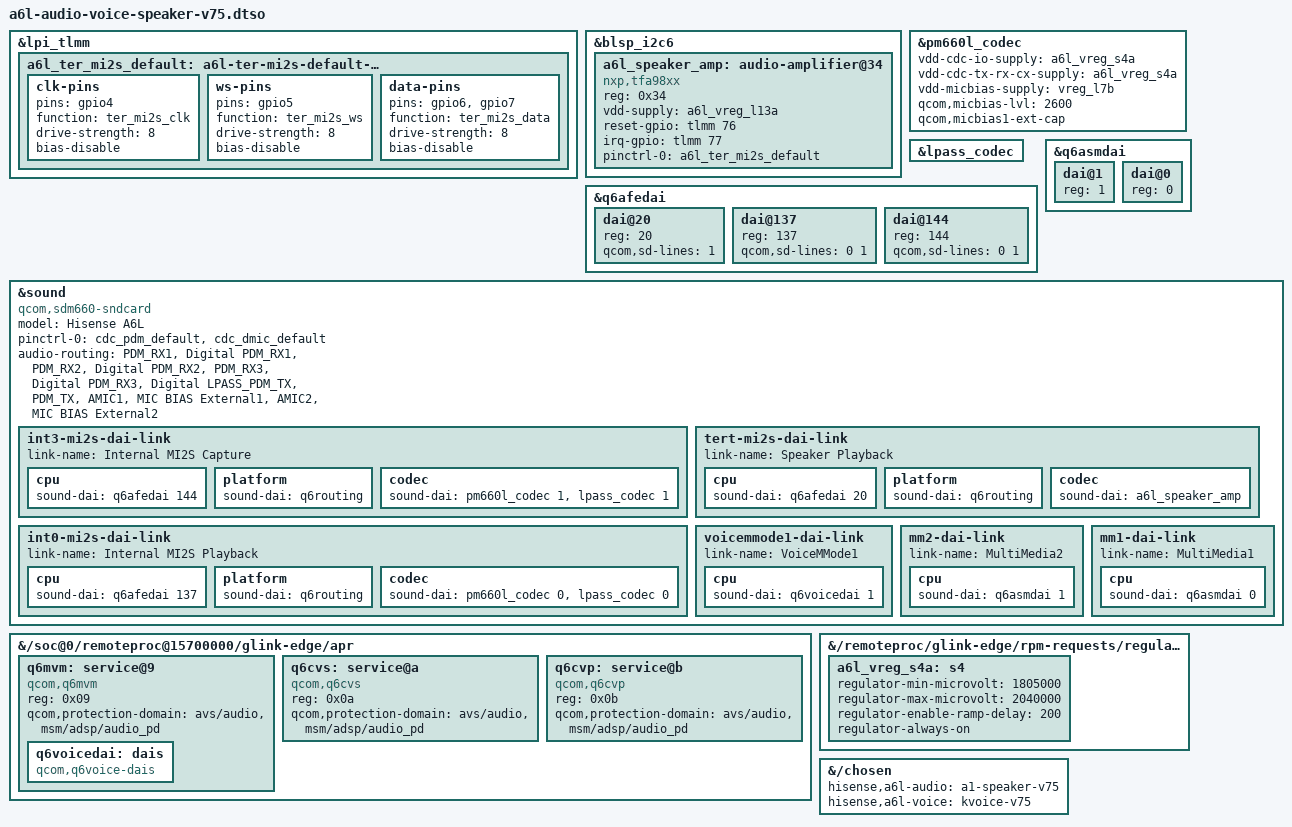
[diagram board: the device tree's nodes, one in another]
// SPDX-License-Identifier: GPL-2.0-only
// V75 CANDIDATE (kvoice agent, 24 Sep 2026), never booted. CALL AUDIO: q6voice (CVD: MVM/CVS/CVP APR services) + a
// "VoiceMMode1" front end (stock: VoiceMMode1 FE, INT0_MI2S_RX_Voice Mixer VoiceMMode1 = mainline LPI_MI2S_RX_0 Voice Mixer
// VoiceMMode1, VoiceMMode1_Tx Mixer INT3_MI2S_TX_MMode1 = mainline VoiceMMode1 Capture Mixer LPI_MI2S_TX_3).
// Kernel: sound/soc/qcom/qdsp6 q6voice series (sc7280-mainline PR #32, Stephan Gerhold / Richard Acayan) + a6l-q6voice-sdm660-v75.patch
// (LPI port routes, CVD version auto-detect). Modules: q6voice-common q6mvm q6cvs q6cvp q6voice q6voice-dai.
// fdtoverlay (and the kernel overlay code) PREPEND new child nodes: see docs/audio3-20260924.md; link order is asserted by
// tools/check-voice-dt-links.py <merged.dtb> (FEs MultiMedia1, MultiMedia2, VoiceMMode1 first, then the q6routing BEs).
// VARIANT: base WITHOUT sound links (use INSTEAD of a6l-audio-speaker-v75.dtso). = a6l-audio-speaker-v75.dtso + the q6voice services and a VoiceMMode1 FE
// written just before mm2 in this REVERSED list -> merged: MultiMedia1, MultiMedia2, VoiceMMode1, [Speaker], Int Playback, Int Capture.
// Correct with the stock and the patched q6asm-dai. ---- original audio3 header follows ----
// SPDX-License-Identifier: GPL-2.0-only
// V75 CANDIDATE (audio3 agent, 24 Sep 2026), never booted. For a base WITHOUT sound links (use INSTEAD of
// a6l-audio-internal-v75.dtso). = a6l-audio-speaker-v74.dtso + q6asm-dais children reversed in the source so that the merged
// DTB has dai@0, dai@1 (index == reg; correct with the stock AND the patched q6asm-dai.ko). Speaker optional at run time with
// the apply-a6l-optional-v75.sh TFA driver (stub DAI on amp failure); build-time requirements as in a6l-audio-speaker-onbase-v75.dtso.
// --- original v74 notes ---
// SPDX-License-Identifier: GPL-2.0-only
// V74 CANDIDATE (audio2 agent, 23 Sep 2026), never booted. SUPERSET of a6l-audio-internal.dtso: use it INSTEAD of that file
// (not on top of it). Adds the loudspeaker path: NXP TFA9894 smart amp (I2C 0x34 on c1b6000 = blsp_i2c6) fed by TERTIARY MI2S
// (AFE port 0x1004, LPI gpio4 SCK / gpio5 WS / gpio6 SD0 / gpio7 SD1, stock "func4").
// Needs, before the card can bind (otherwise the WHOLE card defers, headset included):
//   * pinctrl-sdm660-lpass-lpi.ko rebuilt with a6l-lpi-ter-mi2s-v74.patch (functions ter_mi2s_clk/ws/data), and
//   * snd-soc-tfa98xx.ko (tfa98xx-a6l port) loaded before the machine driver, /lib/firmware/tfa98xx.cnt (stock container).
// Stock facts (firmware/extracted/device-trees/stock-00.dts): tfa98xx@34 { vdd-supply = pm660_l13; reset-gpio = tlmm 76;
// irq-gpio = tlmm 77 }, qcom,msm-dai-q6-mi2s-tert { rx-lines = 0x2 (SD1), tx-lines = 0x1 (SD0 = amp feedback, unused here) },
// audio_platform_info: SND_DEVICE_OUT_SPEAKER -> TERT_MI2S_RX; mixer_paths "speaker": TERT_MI2S_RX Audio Mixer MultiMedia1 = 1.
// sm8250.c already handles TERTIARY_MI2S_RX (TER_MI2S_IBIT 1.536 MHz, CPU = clock master, codec BC_FC I2S).
/dts-v1/;
/plugin/;

&lpi_tlmm {
    a6l_ter_mi2s_default: a6l-ter-mi2s-default-state {
        clk-pins { pins = "gpio4"; function = "ter_mi2s_clk"; drive-strength = <8>; bias-disable; };
        ws-pins { pins = "gpio5"; function = "ter_mi2s_ws"; drive-strength = <8>; bias-disable; };
        data-pins { pins = "gpio6", "gpio7"; function = "ter_mi2s_data"; drive-strength = <8>; bias-disable; };
    };
};

&blsp_i2c6 {
    #address-cells = <1>;
    #size-cells = <0>;
    status = "okay";                               /* already okay (front ALS at 0x47) */
    a6l_speaker_amp: audio-amplifier@34 {
        compatible = "nxp,tfa98xx";                /* tfa98xx-a6l driver; also accepts "tfa,tfa9894" */
        reg = <0x34>;
        vdd-supply = <&a6l_vreg_l13a>;             /* pm660 L13 1.8 V (the driver does not switch it; already on) */
        reset-gpio = <&tlmm 76 0>;                 /* GPIO_ACTIVE_HIGH, as stock */
        irq-gpio = <&tlmm 77 0>;
        pinctrl-names = "default";
        pinctrl-0 = <&a6l_ter_mi2s_default>;       /* LPI pins muxed when the amp probes (stock switches active/sleep) */
        #sound-dai-cells = <0>;
    };
};

&pm660l_codec {
    vdd-cdc-io-supply = <&a6l_vreg_s4a>;
    vdd-cdc-tx-rx-cx-supply = <&a6l_vreg_s4a>;
    vdd-micbias-supply = <&vreg_l7b>;
    qcom,micbias-lvl = <2600>;
    qcom,micbias1-ext-cap;
    status = "okay";
};
&lpass_codec { status = "okay"; };

&q6afedai {
    #address-cells = <1>;
    #size-cells = <0>;
    dai@20 { reg = <20>; qcom,sd-lines = <1>; };      /* TERTIARY_MI2S_RX: stock rx-lines 0x2 = SD1 (gpio7) */
    dai@137 { reg = <137>; qcom,sd-lines = <0 1>; };  /* LPI_MI2S_RX_0 */
    dai@144 { reg = <144>; qcom,sd-lines = <0 1>; };  /* LPI_MI2S_TX_3 */
};
&q6asmdai {
    #address-cells = <1>;
    #size-cells = <0>;
    dai@1 { reg = <1>; };   /* REVERSED ON PURPOSE -> merged: dai@0 (MultiMedia1) first (see a6l-audio-internal-v75.dtso) */
    dai@0 { reg = <0>; };
};

&sound {
    compatible = "qcom,sdm660-sndcard";
    model = "Hisense A6L";
    pinctrl-names = "default";
    pinctrl-0 = <&cdc_pdm_default>, <&cdc_dmic_default>;
    audio-routing = "PDM_RX1", "Digital PDM_RX1", "PDM_RX2", "Digital PDM_RX2", "PDM_RX3", "Digital PDM_RX3",
                    "Digital LPASS_PDM_TX", "PDM_TX", "AMIC1", "MIC BIAS External1", "AMIC2", "MIC BIAS External2";
    // ORDER IS REVERSED ON PURPOSE (see a6l-audio-internal.dtso): fdtoverlay prepends new children, so the merged DTB reads
    // mm1, mm2, tert, int0, int3 -> q6asm-dai probes before the first q6routing platform. Assert MultiMedia1 is link 0.
    int3-mi2s-dai-link {
        link-name = "Internal MI2S Capture";
        cpu { sound-dai = <&q6afedai 144>; };
        platform { sound-dai = <&q6routing>; };
        codec { sound-dai = <&pm660l_codec 1>, <&lpass_codec 1>; };
    };
    int0-mi2s-dai-link {
        link-name = "Internal MI2S Playback";
        cpu { sound-dai = <&q6afedai 137>; };
        platform { sound-dai = <&q6routing>; };
        codec { sound-dai = <&pm660l_codec 0>, <&lpass_codec 0>; };
    };
    tert-mi2s-dai-link {
        link-name = "Speaker Playback";
        cpu { sound-dai = <&q6afedai 20>; };             /* TERTIARY_MI2S_RX */
        platform { sound-dai = <&q6routing>; };
        codec { sound-dai = <&a6l_speaker_amp>; };
    };
    voicemmode1-dai-link { link-name = "VoiceMMode1"; cpu { sound-dai = <&q6voicedai 1>; }; };  /* kvoice: merged -> after MultiMedia2 */
    mm2-dai-link { link-name = "MultiMedia2"; cpu { sound-dai = <&q6asmdai 1>; }; };
    mm1-dai-link { link-name = "MultiMedia1"; cpu { sound-dai = <&q6asmdai 0>; }; };
};

/ {
    /* CVD services on the ADSP APR bus (same PD as q6afe/q6asm/q6adm in sdm630.dtsi). APR_SVC_ADSP_MVM/CVS/CVP = 9/0xa/0xb */
    fragment@80 {
        target-path = "/soc@0/remoteproc@15700000/glink-edge/apr";
        __overlay__ {
            #address-cells = <1>;
            #size-cells = <0>;
            q6mvm: service@9 {
                compatible = "qcom,q6mvm";
                reg = <0x09>;
                qcom,protection-domain = "avs/audio", "msm/adsp/audio_pd";
                q6voicedai: dais {
                    compatible = "qcom,q6voice-dais";
                    #sound-dai-cells = <1>;     /* <&q6voicedai 1> = VOICEMMODE1 (index == id: CS_VOICE 0, VOICEMMODE1 1) */
                    /* no qcom,cvd-v2.3 / qcom,cvd-v2.2: q6voice asks MVM (VSS_IVERSION_CMD_GET); q6voice.cvd_mode= overrides */
                };
            };
            q6cvs: service@a {
                compatible = "qcom,q6cvs";
                reg = <0x0a>;
                qcom,protection-domain = "avs/audio", "msm/adsp/audio_pd";
            };
            q6cvp: service@b {
                compatible = "qcom,q6cvp";
                reg = <0x0b>;
                qcom,protection-domain = "avs/audio", "msm/adsp/audio_pd";
            };
        };
    };
    fragment@90 {
        target-path = "/remoteproc/glink-edge/rpm-requests/regulators-1";
        __overlay__ { a6l_vreg_s4a: s4 { regulator-min-microvolt = <1805000>; regulator-max-microvolt = <2040000>; regulator-enable-ramp-delay = <200>; regulator-always-on; }; };
    };
    fragment@91 { target-path = "/chosen"; __overlay__ { hisense,a6l-audio = "a1-speaker-v75"; hisense,a6l-voice = "kvoice-v75"; }; };
};
